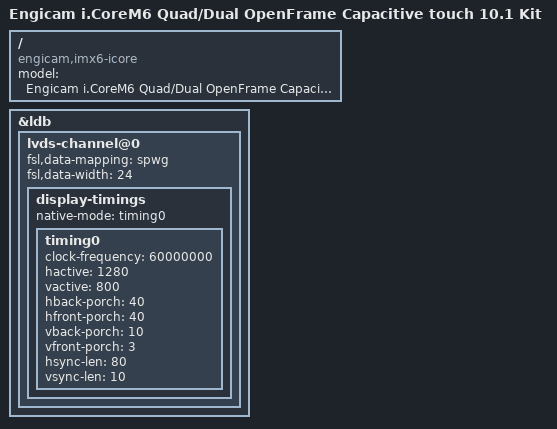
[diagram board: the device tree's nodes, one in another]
// SPDX-License-Identifier: (GPL-2.0+ OR MIT)
/*
 * Copyright (C) 2016 Amarula Solutions B.V.
 * Copyright (C) 2016 Engicam S.r.l.
 */

/dts-v1/;

#include "imx6q.dtsi"
#include "imx6qdl-icore.dtsi"

/ {
	model = "Engicam i.CoreM6 Quad/Dual OpenFrame Capacitive touch 10.1 Kit";
	compatible = "engicam,imx6-icore", "fsl,imx6q";
};

&ldb {
	status = "okay";

	lvds-channel@0 {
		fsl,data-mapping = "spwg";
		fsl,data-width = <24>;
		status = "okay";

		display-timings {
			native-mode = <&timing0>;
			timing0: timing0 {
				clock-frequency = <60000000>;
				hactive = <1280>;
				vactive = <800>;
				hback-porch = <40>;
				hfront-porch = <40>;
				vback-porch = <10>;
				vfront-porch = <3>;
				hsync-len = <80>;
				vsync-len = <10>;
			};
		};
	};
};
